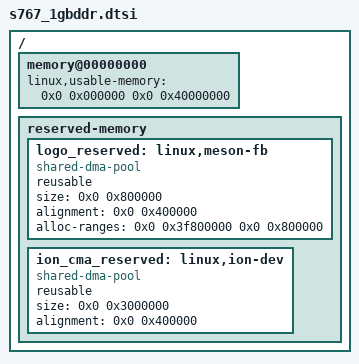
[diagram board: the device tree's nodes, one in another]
/*
 * Copyright (c) 2021, Sonos, Inc.
 *
 * SPDX-License-Identifier:     GPL-2.0
 *
 * for 1GB device
 */


/ {
       memory@00000000 {
               device_type = "memory";
               linux,usable-memory = <0x0 0x000000 0x0 0x40000000>;
       };
       reserved-memory {
               logo_reserved:linux,meson-fb {
                       compatible = "shared-dma-pool";
                       reusable;
                       size = <0x0 0x800000>;
                       alignment = <0x0 0x400000>;
                       alloc-ranges = <0x0 0x3f800000 0x0 0x800000>;
               };
               ion_cma_reserved:linux,ion-dev {
                       compatible = "shared-dma-pool";
                       reusable;
                       size = <0x0 0x3000000>;
                       alignment = <0x0 0x400000>;
               };
       };
};
